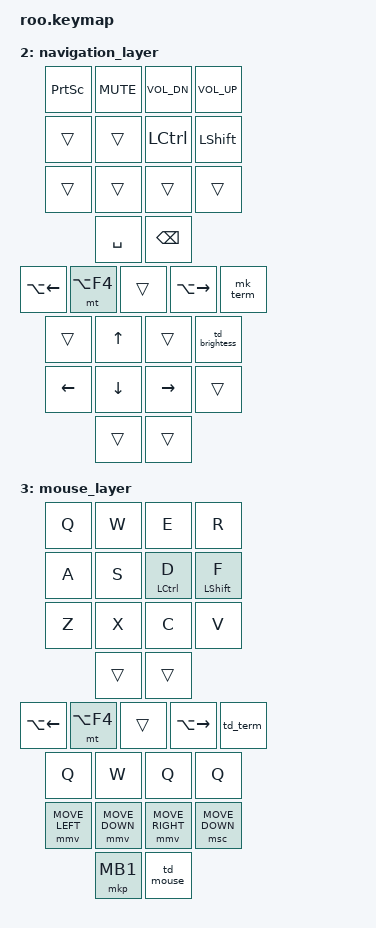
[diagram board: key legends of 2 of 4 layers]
#include <dt-bindings/zmk/behaviors.h>
#include <dt-bindings/zmk/keys.h>
#include <dt-bindings/zmk/mouse.h>
// LOOK UP PAUSE BREAK/ 
/ {
    macros {
        // Back Window
            m_NEXT_WINDOW: m_NEXT_WINDOW {
            compatible = "zmk,behavior-macro";
            #binding-cells = <0>;
            bindings 
                = <&macro_press &kp LSHFT>
                , <&macro_tap &kp LS(LA(TAB))>
                , <&macro_release &kp LSHIFT>
                ;
        };
        // Terminal start
        mk_term:mk_term {
            compatible = "zmk,behavior-macro";
            #binding-cells = <0>;
            bindings = 
                <&macro_tap &kp LG(X)>,
                <&macro_wait_time 117>,
                <&macro_tap &kp I>;
        };
        clear_term_bg:clear_term_bg{
            compatible = "zmk,behavior-macro";
            #binding-cells = <0>;
            bindings = 
               <&macro_tap &kp LG(D)>,
                <&macro_tap &kp LALT TAB>;
        };
    };

    behaviors {
        td_brightness: td_brightness {
            compatible = "zmk,behavior-tap-dance";
            #binding-cells = <0>;
            tapping-term-ms = <200>;
            bindings = <&mt C_BRI_UP &trans>, <&mt C_BRI_DN &trans>;
        };
        td_vol: td_vol {
            compatible = "zmk,behavior-tap-dance";
            #binding-cells = <0>;
            tapping-term-ms = <200>;
            bindings = <&mt C_VOL_UP C_VOL_DN>, <&mt C_MUTE C_VOL_UP>;
        };
        td_mouse: td_mouse {
            compatible = "zmk,behavior-tap-dance";
            #binding-cells = <0>;
            tapping-term-ms = <200>;
            bindings = <&mt &mkp MB2 &mkp MB2>, <&mt &mkp MB3 &mkp MB3>;
        };
    };
combos {
    compatible = "zmk,combos";
    combo_ESCAPE {
        timeout-ms = <200>;
        key-positions = <0 1>;
        bindings = <&kp ESCAPE>;
        layers = <0>;
    };
    combo_TO_MOUSE {
        timeout_ms = <200>;
        key-positions = <26 27>;
        bindings = <&to 2>;
        layers = <0>;
    };
    combo_TO_DEFAULT{ 
        timeout-ms = <200>;
        key-positions = <26 27>;
        bindings = <&to 0>;
        layers = <2>;
    };
    combo_GUI { 
        timeout-ms = <200>;
        key-positions = <8 9>;
        bindings = <&sk LGUI>;
        layers = <0>;
    };
    combo_DEL { 
        timeout-ms = <200>;
        key-positions = <3 12>;
        bindings = <&kp DELETE >;
        layers = <0>;
    };
    combo_ENTER {
        timeout-ms = <200>;
        key-positions = <24 25>;
        bindings = <&kp ENTER>;
        layers = <0>;
    };
    combo_tab {
        timeout-ms = <200>;
        key-positions =<4 5>;
        bindings = <&kp TAB>;
        layers = <0>;
        };
    combo_G {
        timeout-ms = <200>;
        key-positions =<3 7>;
        bindings = <&kp G>;
        layers = <0>;
    };
    combo_B {
        timeout-ms = <200>;
        key-positions =<7 11>;
        bindings = <&kp B>;
        layers = <0>;
    };
    combo_V {
        timeout-ms = <200>;
        key-positions =<2 6>;
        bindings = <&kp V>;
        layers = <0>;
    };
    combo_K {
        timeout-ms = <200>;
        key-positions =<14 18>;
        bindings = <&kp K>;
        layers = <0>;
    };
    combo_J {
        timeout-ms = <200>;
        key-positions =<18 22>;
        bindings = <&kp J>;
        layers = <0>;
    };
    combo_M {
        timeout-ms = <200>;
        key-positions = <15 19>;
        bindings = <&kp M>;
        layers = <0>;
    };
    combo_NEXT_TAB {
        timeout-ms = <200>;
        key-positions = <20 24>;
        bindings = <&kp LC(TAB)>;
        layers = <0>;
    };
    combo_NEXT_WINDOW {
        timeout-ms = <200>;
        key-positions = <21 25>;
        bindings = <&m_NEXT_WINDOW>;
        layers = <0>;
    };
    combo_TD4 {
        timeout-ms = <200>;
        key-positions = <17 22>;
        bindings = <&td_volume>;
        layers = <0>;
    };
    combo_TD14 {
        timeout-ms = <200>;
        key-positions = <16 20>;
        bindings = <&td_brightness>;
        layers = <0>;
    };
    };

    keymap {
        compatible = "zmk,keymap";

        default_layer { // Layer 0
            // -------------------------------------
            // | q | w | f | p           l | u | y | m
            // | a | w | s | t           n | e | i | o
            // | z | x | c | d           h | k | j | v
	    //             |num|bk   sp|dir

            bindings = <
                &kp Q &kp W &kp F &kp P 
                &kp A &kp R &mt LCTRL S &mt LSHIFT T
                &kp Z &kp X &kp C &kp D
                &mo 1 &kp BSPC
                &kp L &kp U &kp Y &kp SEMI 
                &mt RSHIFT N &mt RCTRL E &mt LALT I &kp O 
                &kp H &kp COMMA &kp DOT &kp FSLH
                &kp SPACE &mo 2 
            >;
        };
        number_layer {
            // -------------------------------------
            // | F5| F6| F7| F8          F1| F2| F3| F4
            // | 5 | 6 | 7 | 8           1 | 2 | 3 | 4
            // |hm |end| ` | {}          [] | k | j | v
	    //             | g | b  0 | 1

            bindings = <
                &kp F7 &kp F8 &kp F9 &kp F10
                &kp N6 &kp N7 &mt N8 N9 &kp N0
                &kp HOME &kp END &kp GRAVE &mt LS(RBKT) LS(LBKT)
                &trans &trans
                &mt F1 F11 &mt F2 F12 &mt F4 F3 &mt F6 F5
                &kp N1 &mt N3 N2 &kp N4 &kp N5 
                &mt RBKT LBKT &kp SQT &kp COLON &kp BSLH
                &kp MINUS &kp EQUAL
            >;
        };
        navigation_layer {
            // -------------------------------------
            // |psc|mut|vdn|vup         bka|qut|fwa|trm
            // |   |   |ctr|shf            |up |   |tdb
            // |   |   |   |            lef|dwn|rht|  
	    //             |spc|bk     |   
            bindings = <
                &kp PSCRN &kp C_MUTE &kp C_VOL_DN &kp C_VOL_UP
                &trans &trans &kp LCTRL &kp LSHIFT
                &trans &trans &trans &trans
                &kp SPACE &kp BSPC 

                &kp LA(LEFT) &mt LA(F4) &trans &kp LA(RIGHT) &mk_term
                &trans &kp UP &trans &td_brightess
                &kp LEFT &kp DOWN &kp RIGHT &trans 
                &trans &trans 
            >;
         };
        mouse_layer {
            // -------------------------------------
            // | q | w | e | r          bkb|qut|fwb|trm
            // | a | s |ctD|shF         nxt|mup|nxw|scu
            // | z | x | c | v          mlf|mdn|mrt|scd
	    //             |   |    mb1|tdM
            //  // &kp LC(TAB) &mmv MOVE_UP &m_NEXT_WINDOW &kp WH_U 
            bindings = <
                &kp Q &kp W &kp E &kp R 
                &kp A &kp S &mt LCTRL D &mt LSHIFT F 
                &kp Z &kp X &kp C &kp V 
                &trans &trans

                &kp LA(LEFT) &mt LA(F4) &trans &kp LA(RIGHT) &td_term
                &kp Q &kp W &kp Q &kp Q
                &mmv MOVE_LEFT &mmv MOVE_DOWN &mmv MOVE_RIGHT &msc MOVE_DOWN
                &mkp MB1 &td_mouse
            >;
        };
 };

 
 

